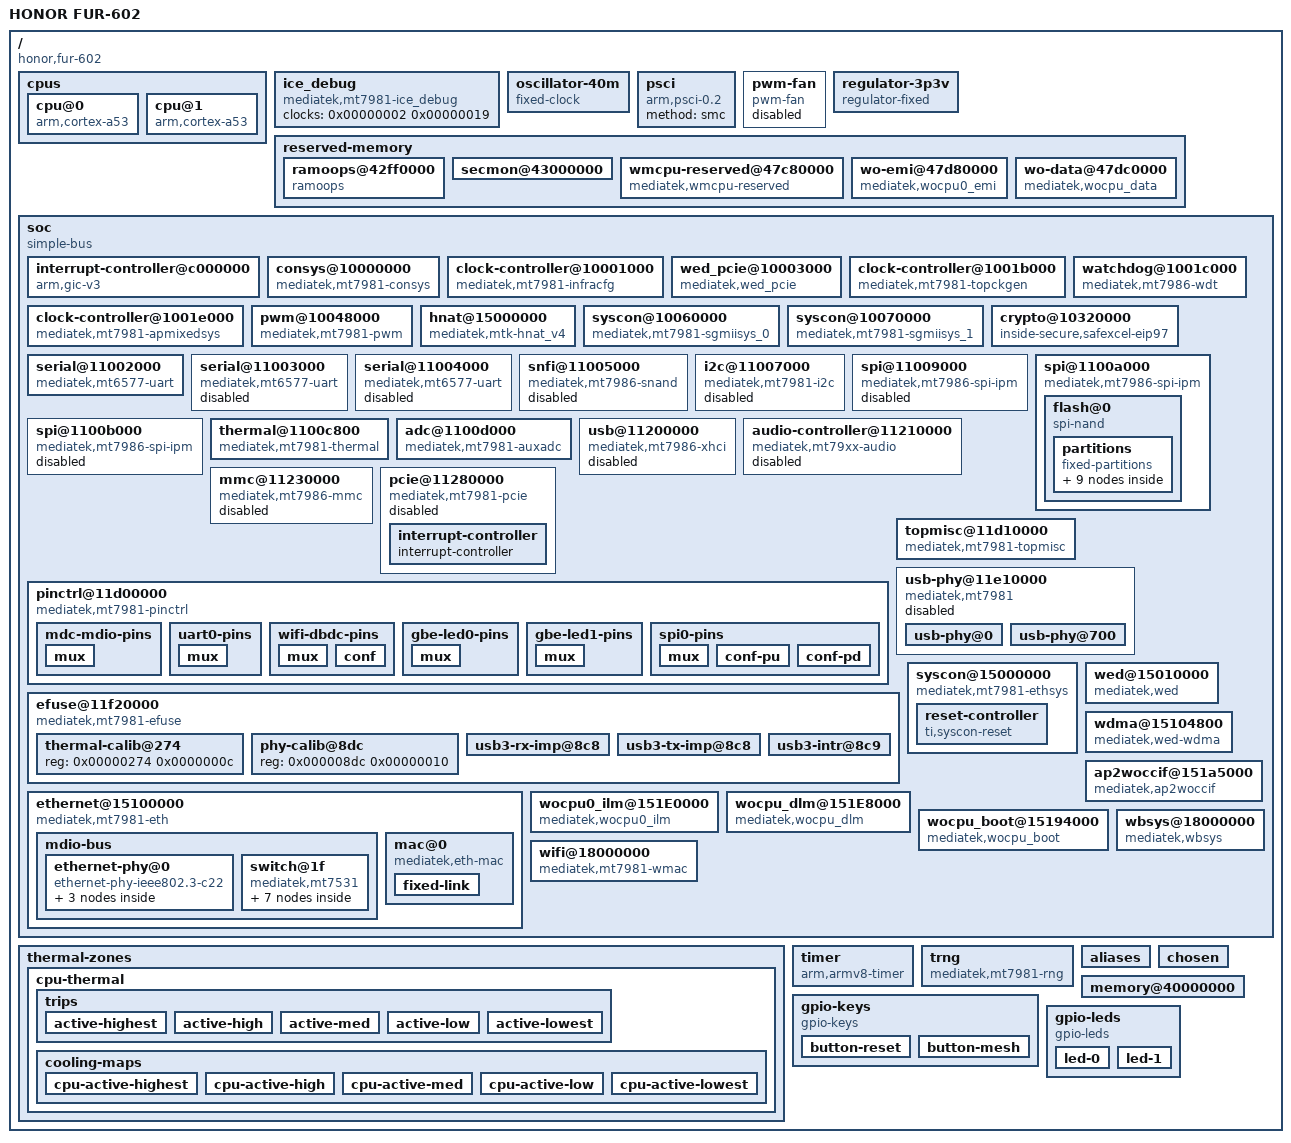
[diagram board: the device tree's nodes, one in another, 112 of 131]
/dts-v1/;
// version:		17
// last_comp_version:	16
// boot_cpuid_phys:	0x0

/ {
    mediatek,env-size = "0x20000";
    mediatek,env-offset = "0x0";
    mediatek,env-part = "u-boot-env";
    compatible = "honor,fur-602", "mediatek,mt7981";
    interrupt-parent = <0x00000001>;
    #address-cells = <0x00000002>;
    #size-cells = <0x00000002>;
    model = "HONOR FUR-602";
    cpus {
        #address-cells = <0x00000001>;
        #size-cells = <0x00000000>;
        cpu@0 {
            compatible = "arm,cortex-a53";
            reg = <0x00000000>;
            device_type = "cpu";
            enable-method = "psci";
        };
        cpu@1 {
            compatible = "arm,cortex-a53";
            reg = <0x00000001>;
            device_type = "cpu";
            enable-method = "psci";
        };
    };
    ice_debug {
        compatible = "mediatek,mt7981-ice_debug", "mediatek,mt2701-ice_debug";
        clocks = <0x00000002 0x00000019>;
        clock-names = "ice_dbg";
        phandle = <0x00000020>;
    };
    oscillator-40m {
        compatible = "fixed-clock";
        clock-frequency = <0x02625a00>;
        clock-output-names = "clkxtal";
        #clock-cells = <0x00000000>;
        phandle = <0x00000021>;
    };
    psci {
        compatible = "arm,psci-0.2";
        method = "smc";
    };
    pwm-fan {
        compatible = "pwm-fan";
        cooling-levels = <0x00000000 0x0000003f 0x0000005f 0x0000007f 0x0000009f 0x000000bf 0x000000df 0x000000ff>;
        #cooling-cells = <0x00000002>;
        status = "disabled";
        phandle = <0x0000001a>;
    };
    regulator-3p3v {
        compatible = "regulator-fixed";
        regulator-name = "fixed-3.3V";
        regulator-min-microvolt = <0x00325aa0>;
        regulator-max-microvolt = <0x00325aa0>;
        regulator-boot-on;
        regulator-always-on;
        phandle = <0x0000000d>;
    };
    reserved-memory {
        ranges;
        #address-cells = <0x00000002>;
        #size-cells = <0x00000002>;
        ramoops@42ff0000 {
            compatible = "ramoops";
            reg = <0x00000000 0x42ff0000 0x00000000 0x00010000>;
            record-size = <0x00001000>;
        };
        secmon@43000000 {
            reg = <0x00000000 0x43000000 0x00000000 0x00030000>;
            no-map;
            phandle = <0x00000022>;
        };
        wmcpu-reserved@47c80000 {
            compatible = "mediatek,wmcpu-reserved";
            reg = <0x00000000 0x47c80000 0x00000000 0x00100000>;
            no-map;
            phandle = <0x00000004>;
        };
        wo-emi@47d80000 {
            compatible = "mediatek,wocpu0_emi";
            reg = <0x00000000 0x47d80000 0x00000000 0x00040000>;
            no-map;
            shared = <0x00000000>;
            phandle = <0x00000023>;
        };
        wo-data@47dc0000 {
            compatible = "mediatek,wocpu_data";
            reg = <0x00000000 0x47dc0000 0x00000000 0x00240000>;
            no-map;
            shared = <0x00000001>;
            phandle = <0x00000024>;
        };
    };
    soc {
        compatible = "simple-bus";
        ranges;
        #address-cells = <0x00000002>;
        #size-cells = <0x00000002>;
        interrupt-controller@c000000 {
            compatible = "arm,gic-v3";
            reg = <0x00000000 0x0c000000 0x00000000 0x00040000 0x00000000 0x0c080000 0x00000000 0x00200000>;
            interrupt-parent = <0x00000001>;
            interrupts = <0x00000001 0x00000009 0x00000004>;
            interrupt-controller;
            #interrupt-cells = <0x00000003>;
            phandle = <0x00000001>;
        };
        consys@10000000 {
            compatible = "mediatek,mt7981-consys";
            reg = <0x00000000 0x10000000 0x00000000 0x08600000>;
            clocks = <0x00000003 0x0000005f 0x00000003 0x0000005c>;
            clock-names = "mcu", "ap2conn";
            memory-region = <0x00000004>;
            phandle = <0x00000025>;
        };
        clock-controller@10001000 {
            compatible = "mediatek,mt7981-infracfg", "syscon";
            reg = <0x00000000 0x10001000 0x00000000 0x00001000>;
            #clock-cells = <0x00000001>;
            phandle = <0x00000002>;
        };
        wed_pcie@10003000 {
            compatible = "mediatek,wed_pcie";
            reg = <0x00000000 0x10003000 0x00000000 0x00000010>;
            phandle = <0x00000026>;
        };
        clock-controller@1001b000 {
            compatible = "mediatek,mt7981-topckgen", "syscon";
            reg = <0x00000000 0x1001b000 0x00000000 0x00001000>;
            #clock-cells = <0x00000001>;
            phandle = <0x00000003>;
        };
        watchdog@1001c000 {
            compatible = "mediatek,mt7986-wdt", "mediatek,mt6589-wdt";
            reg = <0x00000000 0x1001c000 0x00000000 0x00001000>;
            interrupts = <0x00000000 0x0000006e 0x00000004>;
            #reset-cells = <0x00000001>;
            status = "okay";
            phandle = <0x00000027>;
        };
        clock-controller@1001e000 {
            compatible = "mediatek,mt7981-apmixedsys", "syscon";
            reg = <0x00000000 0x1001e000 0x00000000 0x00001000>;
            #clock-cells = <0x00000001>;
            phandle = <0x0000000a>;
        };
        pwm@10048000 {
            compatible = "mediatek,mt7981-pwm";
            reg = <0x00000000 0x10048000 0x00000000 0x00001000>;
            clocks = <0x00000002 0x0000000e 0x00000002 0x0000000d 0x00000002 0x0000000f 0x00000002 0x00000010 0x00000002 0x00000011>;
            clock-names = "top", "main", "pwm1", "pwm2", "pwm3";
            #pwm-cells = <0x00000002>;
            phandle = <0x00000028>;
        };
        hnat@15000000 {
            compatible = "mediatek,mtk-hnat_v4";
            reg = <0x00000000 0x15100000 0x00000000 0x00080000>;
            resets = <0x00000005 0x00000000>;
            reset-names = "mtketh";
            mtketh-wan = "eth1";
            mtketh-lan = "eth0";
            mtketh-max-gmac = <0x00000002>;
            mtketh-ppe-num = <0x00000002>;
            ext-devices-prefix = "usb", "wwan", "rmnet", "eth2", "eth3", "eth4";
            phandle = <0x00000029>;
        };
        syscon@10060000 {
            compatible = "mediatek,mt7981-sgmiisys_0", "syscon";
            reg = <0x00000000 0x10060000 0x00000000 0x00001000>;
            mediatek,pnswap;
            #clock-cells = <0x00000001>;
            phandle = <0x00000011>;
        };
        syscon@10070000 {
            compatible = "mediatek,mt7981-sgmiisys_1", "syscon";
            reg = <0x00000000 0x10070000 0x00000000 0x00001000>;
            #clock-cells = <0x00000001>;
            phandle = <0x00000012>;
        };
        crypto@10320000 {
            compatible = "inside-secure,safexcel-eip97";
            reg = <0x00000000 0x10320000 0x00000000 0x00040000>;
            interrupts = <0x00000000 0x00000074 0x00000004 0x00000000 0x00000075 0x00000004 0x00000000 0x00000076 0x00000004 0x00000000 0x00000077 0x00000004>;
            interrupt-names = "ring0", "ring1", "ring2", "ring3";
            clocks = <0x00000003 0x00000042>;
            clock-names = "top_eip97_ck";
            assigned-clocks = <0x00000003 0x00000063>;
            assigned-clock-parents = <0x00000003 0x00000015>;
            phandle = <0x0000002a>;
        };
        serial@11002000 {
            compatible = "mediatek,mt6577-uart";
            reg = <0x00000000 0x11002000 0x00000000 0x00000400>;
            interrupts = <0x00000000 0x0000007b 0x00000004>;
            clocks = <0x00000002 0x00000001 0x00000002 0x0000001f>;
            clock-names = "baud", "bus";
            assigned-clocks = <0x00000003 0x00000050 0x00000002 0x00000001>;
            assigned-clock-parents = <0x00000003 0x00000000 0x00000003 0x00000050>;
            pinctrl-0 = <0x00000006>;
            pinctrl-names = "default";
            status = "okay";
            phandle = <0x0000002b>;
        };
        serial@11003000 {
            compatible = "mediatek,mt6577-uart";
            reg = <0x00000000 0x11003000 0x00000000 0x00000400>;
            interrupts = <0x00000000 0x0000007c 0x00000004>;
            clocks = <0x00000002 0x00000002 0x00000002 0x00000020>;
            clock-names = "baud", "bus";
            assigned-clocks = <0x00000003 0x00000050 0x00000002 0x00000002>;
            assigned-clock-parents = <0x00000003 0x00000000 0x00000003 0x00000050>;
            status = "disabled";
            phandle = <0x0000002c>;
        };
        serial@11004000 {
            compatible = "mediatek,mt6577-uart";
            reg = <0x00000000 0x11004000 0x00000000 0x00000400>;
            interrupts = <0x00000000 0x0000007d 0x00000004>;
            clocks = <0x00000002 0x00000003 0x00000002 0x00000021>;
            clock-names = "baud", "bus";
            assigned-clocks = <0x00000003 0x00000050 0x00000002 0x00000003>;
            assigned-clock-parents = <0x00000003 0x00000000 0x00000003 0x00000050>;
            status = "disabled";
            phandle = <0x0000002d>;
        };
        snfi@11005000 {
            compatible = "mediatek,mt7986-snand";
            reg = <0x00000000 0x11005000 0x00000000 0x00001000 0x00000000 0x11006000 0x00000000 0x00001000>;
            reg-names = "nfi", "ecc";
            interrupts = <0x00000000 0x00000079 0x00000004>;
            clocks = <0x00000002 0x00000025 0x00000002 0x00000024 0x00000002 0x00000026>;
            clock-names = "pad_clk", "nfi_clk", "nfi_hclk";
            assigned-clocks = <0x00000003 0x0000004d 0x00000003 0x0000004c>;
            assigned-clock-parents = <0x00000003 0x00000006 0x00000003 0x00000006>;
            #address-cells = <0x00000001>;
            #size-cells = <0x00000000>;
            status = "disabled";
            phandle = <0x0000002e>;
        };
        i2c@11007000 {
            compatible = "mediatek,mt7981-i2c";
            reg = <0x00000000 0x11007000 0x00000000 0x00001000 0x00000000 0x10217080 0x00000000 0x00000080>;
            interrupts = <0x00000000 0x00000088 0x00000004>;
            clock-div = <0x00000001>;
            clocks = <0x00000002 0x0000001e 0x00000002 0x0000001a 0x00000002 0x00000033 0x00000002 0x00000034>;
            clock-names = "main", "dma", "arb", "pmic";
            #address-cells = <0x00000001>;
            #size-cells = <0x00000000>;
            status = "disabled";
            phandle = <0x0000002f>;
        };
        spi@11009000 {
            compatible = "mediatek,mt7986-spi-ipm", "mediatek,spi-ipm";
            reg = <0x00000000 0x11009000 0x00000000 0x00000100>;
            interrupts = <0x00000000 0x0000008e 0x00000004>;
            clocks = <0x00000003 0x00000002 0x00000003 0x0000004e 0x00000002 0x00000022 0x00000002 0x00000023>;
            clock-names = "parent-clk", "sel-clk", "spi-clk", "hclk";
            #address-cells = <0x00000001>;
            #size-cells = <0x00000000>;
            status = "disabled";
            phandle = <0x00000030>;
        };
        spi@1100a000 {
            compatible = "mediatek,mt7986-spi-ipm", "mediatek,spi-ipm";
            reg = <0x00000000 0x1100a000 0x00000000 0x00000100>;
            interrupts = <0x00000000 0x0000008c 0x00000004>;
            clocks = <0x00000003 0x00000002 0x00000003 0x0000004e 0x00000002 0x00000027 0x00000002 0x00000029>;
            clock-names = "parent-clk", "sel-clk", "spi-clk", "hclk";
            #address-cells = <0x00000001>;
            #size-cells = <0x00000000>;
            status = "okay";
            pinctrl-names = "default";
            pinctrl-0 = <0x00000007>;
            phandle = <0x00000031>;
            flash@0 {
                #address-cells = <0x00000001>;
                #size-cells = <0x00000001>;
                compatible = "spi-nand";
                reg = <0x00000000>;
                spi-max-frequency = <0x03197500>;
                spi-tx-bus-width = <0x00000004>;
                spi-rx-bus-width = <0x00000004>;
                spi-cal-enable;
                spi-cal-mode = "read-data";
                spi-cal-datalen = <0x00000007>;
                spi-cal-data = [53 50 49 4e 41 4e 44];
                spi-cal-addrlen = <0x00000005>;
                spi-cal-addr = <0x00000000 0x00000000 0x00000000 0x00000000 0x00000000>;
                mediatek,nmbm;
                mediatek,bmt-max-ratio = <0x00000001>;
                mediatek,bmt-max-reserved-blocks = <0x00000040>;
                phandle = <0x00000032>;
                partitions {
                    compatible = "fixed-partitions";
                    #address-cells = <0x00000001>;
                    #size-cells = <0x00000001>;
                    partition@0 {
                        label = "BL2";
                        reg = <0x00000000 0x00100000>;
                        read-only;
                    };
                    partition@100000 {
                        label = "u-boot-env";
                        reg = <0x00100000 0x00080000>;
                    };
                    partition@180000 {
                        label = "Factory";
                        reg = <0x00180000 0x001e0000>;
                        read-only;
                        nvmem-layout {
                            compatible = "fixed-layout";
                            #address-cells = <0x00000001>;
                            #size-cells = <0x00000001>;
                            eeprom@0 {
                                reg = <0x00000000 0x00001000>;
                                phandle = <0x00000018>;
                            };
                            macaddr@2a {
                                compatible = "mac-base";
                                reg = <0x0000002a 0x00000006>;
                                #nvmem-cell-cells = <0x00000001>;
                                phandle = <0x00000016>;
                            };
                        };
                    };
                    partition@360000 {
                        label = "Trace";
                        reg = <0x00360000 0x00020000>;
                        read-only;
                    };
                    partition@380000 {
                        label = "FIP";
                        reg = <0x00380000 0x00200000>;
                        read-only;
                    };
                    partition@580000 {
                        label = "ubi";
                        reg = <0x00580000 0x07200000>;
                    };
                };
            };
        };
        spi@1100b000 {
            compatible = "mediatek,mt7986-spi-ipm", "mediatek,spi-ipm";
            reg = <0x00000000 0x1100b000 0x00000000 0x00000100>;
            interrupts = <0x00000000 0x0000008d 0x00000004>;
            clocks = <0x00000003 0x00000002 0x00000003 0x0000004f 0x00000002 0x00000028 0x00000002 0x0000002a>;
            clock-names = "parent-clk", "sel-clk", "spi-clk", "hclk";
            #address-cells = <0x00000001>;
            #size-cells = <0x00000000>;
            status = "disabled";
            phandle = <0x00000033>;
        };
        thermal@1100c800 {
            compatible = "mediatek,mt7981-thermal", "mediatek,mt7986-thermal";
            reg = <0x00000000 0x1100c800 0x00000000 0x00000800>;
            interrupts = <0x00000000 0x0000008a 0x00000004>;
            clocks = <0x00000002 0x0000001d 0x00000002 0x00000030>;
            clock-names = "therm", "auxadc";
            nvmem-cells = <0x00000008>;
            nvmem-cell-names = "calibration-data";
            #thermal-sensor-cells = <0x00000001>;
            mediatek,auxadc = <0x00000009>;
            mediatek,apmixedsys = <0x0000000a>;
            phandle = <0x00000019>;
        };
        adc@1100d000 {
            compatible = "mediatek,mt7981-auxadc", "mediatek,mt7986-auxadc", "mediatek,mt7622-auxadc";
            reg = <0x00000000 0x1100d000 0x00000000 0x00001000>;
            clocks = <0x00000002 0x00000030 0x00000002 0x00000031>;
            clock-names = "main", "32k";
            #io-channel-cells = <0x00000001>;
            phandle = <0x00000009>;
        };
        usb@11200000 {
            compatible = "mediatek,mt7986-xhci", "mediatek,mtk-xhci";
            reg = <0x00000000 0x11200000 0x00000000 0x00002e00 0x00000000 0x11203e00 0x00000000 0x00000100>;
            reg-names = "mac", "ippc";
            interrupts = <0x00000000 0x000000ad 0x00000004>;
            clocks = <0x00000002 0x00000037 0x00000002 0x00000038 0x00000002 0x00000035 0x00000002 0x00000036 0x00000003 0x0000006b>;
            clock-names = "sys_ck", "ref_ck", "mcu_ck", "dma_ck", "xhci_ck";
            phys = <0x0000000b 0x00000003 0x0000000c 0x00000004>;
            vusb33-supply = <0x0000000d>;
            status = "disabled";
            phandle = <0x00000034>;
        };
        audio-controller@11210000 {
            compatible = "mediatek,mt79xx-audio";
            reg = <0x00000000 0x11210000 0x00000000 0x00009000>;
            interrupts = <0x00000000 0x0000006a 0x00000004>;
            clocks = <0x00000002 0x00000013 0x00000002 0x00000014 0x00000002 0x00000015 0x00000002 0x00000016 0x00000002 0x00000017 0x00000003 0x00000065>;
            clock-names = "aud_bus_ck", "aud_26m_ck", "aud_l_ck", "aud_aud_ck", "aud_eg2_ck", "aud_sel";
            assigned-clocks = <0x00000003 0x00000065 0x00000003 0x00000066 0x00000003 0x00000067 0x00000003 0x00000068>;
            assigned-clock-parents = <0x00000003 0x00000010 0x00000003 0x00000012 0x00000003 0x00000010 0x00000003 0x00000012>;
            status = "disabled";
            phandle = <0x00000035>;
        };
        mmc@11230000 {
            compatible = "mediatek,mt7986-mmc", "mediatek,mt7981-mmc";
            reg = <0x00000000 0x11230000 0x00000000 0x00001000 0x00000000 0x11c20000 0x00000000 0x00001000>;
            interrupts = <0x00000000 0x0000008f 0x00000004>;
            clocks = <0x00000002 0x0000002c 0x00000002 0x0000002d 0x00000002 0x0000002f 0x00000002 0x0000002e>;
            assigned-clocks = <0x00000003 0x00000054 0x00000003 0x00000055>;
            assigned-clock-parents = <0x00000003 0x00000002 0x00000003 0x0000001c>;
            clock-names = "source", "hclk", "axi_cg", "ahb_cg";
            status = "disabled";
            phandle = <0x00000036>;
        };
        pcie@11280000 {
            compatible = "mediatek,mt7981-pcie", "mediatek,mt8192-pcie";
            reg = <0x00000000 0x11280000 0x00000000 0x00004000>;
            reg-names = "pcie-mac";
            ranges = <0x82000000 0x00000000 0x20000000 0x00000000 0x20000000 0x00000000 0x10000000>;
            device_type = "pci";
            interrupts = <0x00000000 0x000000a8 0x00000004>;
            bus-range = <0x00000000 0x000000ff>;
            clocks = <0x00000002 0x00000039 0x00000002 0x0000003a 0x00000002 0x0000003b 0x00000002 0x0000003c>;
            phys = <0x0000000c 0x00000002>;
            phy-names = "pcie-phy";
            interrupt-map-mask = <0x00000000 0x00000000 0x00000000 0x00000007>;
            interrupt-map = <0x00000000 0x00000000 0x00000000 0x00000001 0x0000000e 0x00000000 0x00000000 0x00000000 0x00000000 0x00000002 0x0000000e 0x00000001 0x00000000 0x00000000 0x00000000 0x00000003 0x0000000e 0x00000002 0x00000000 0x00000000 0x00000000 0x00000004 0x0000000e 0x00000003>;
            #interrupt-cells = <0x00000001>;
            #address-cells = <0x00000003>;
            #size-cells = <0x00000002>;
            status = "disabled";
            phandle = <0x00000037>;
            interrupt-controller {
                interrupt-controller;
                #interrupt-cells = <0x00000001>;
                #address-cells = <0x00000000>;
                phandle = <0x0000000e>;
            };
        };
        pinctrl@11d00000 {
            compatible = "mediatek,mt7981-pinctrl";
            reg = <0x00000000 0x11d00000 0x00000000 0x00001000 0x00000000 0x11c00000 0x00000000 0x00001000 0x00000000 0x11c10000 0x00000000 0x00001000 0x00000000 0x11d20000 0x00000000 0x00001000 0x00000000 0x11e00000 0x00000000 0x00001000 0x00000000 0x11e20000 0x00000000 0x00001000 0x00000000 0x11f00000 0x00000000 0x00001000 0x00000000 0x11f10000 0x00000000 0x00001000 0x00000000 0x1000b000 0x00000000 0x00001000>;
            reg-names = "gpio", "iocfg_rt", "iocfg_rm", "iocfg_rb", "iocfg_lb", "iocfg_bl", "iocfg_tm", "iocfg_tl", "eint";
            gpio-controller;
            #gpio-cells = <0x00000002>;
            gpio-ranges = <0x0000000f 0x00000000 0x00000000 0x00000038>;
            interrupt-controller;
            interrupts = <0x00000000 0x000000e1 0x00000004>;
            interrupt-parent = <0x00000001>;
            #interrupt-cells = <0x00000002>;
            phandle = <0x0000000f>;
            mdc-mdio-pins {
                phandle = <0x00000038>;
                mux {
                    function = "eth";
                    groups = "smi_mdc_mdio";
                };
            };
            uart0-pins {
                phandle = <0x00000006>;
                mux {
                    function = "uart";
                    groups = "uart0";
                };
            };
            wifi-dbdc-pins {
                phandle = <0x00000039>;
                mux {
                    function = "eth";
                    groups = "wf0_mode1";
                };
                conf {
                    pins = "WF_HB1", "WF_HB2", "WF_HB3", "WF_HB4", "WF_HB0", "WF_HB0_B", "WF_HB5", "WF_HB6", "WF_HB7", "WF_HB8", "WF_HB9", "WF_HB10", "WF_TOP_CLK", "WF_TOP_DATA", "WF_XO_REQ", "WF_CBA_RESETB", "WF_DIG_RESETB";
                    drive-strength = <0x00000004>;
                };
            };
            gbe-led0-pins {
                phandle = <0x0000003a>;
                mux {
                    function = "led";
                    groups = "gbe_led0";
                };
            };
            gbe-led1-pins {
                phandle = <0x0000003b>;
                mux {
                    function = "led";
                    groups = "gbe_led1";
                };
            };
            spi0-pins {
                phandle = <0x00000007>;
                mux {
                    function = "spi";
                    groups = "spi0", "spi0_wp_hold";
                };
                conf-pu {
                    pins = "SPI0_CS", "SPI0_HOLD", "SPI0_WP";
                    drive-strength = <0x00000008>;
                    bias-pull-up = <0x00000067>;
                };
                conf-pd {
                    pins = "SPI0_CLK", "SPI0_MOSI", "SPI0_MISO";
                    drive-strength = <0x00000008>;
                    bias-pull-down = <0x00000067>;
                };
            };
        };
        topmisc@11d10000 {
            compatible = "mediatek,mt7981-topmisc", "syscon";
            reg = <0x00000000 0x11d10000 0x00000000 0x00010000>;
            #clock-cells = <0x00000001>;
            phandle = <0x00000010>;
        };
        usb-phy@11e10000 {
            compatible = "mediatek,mt7981", "mediatek,generic-tphy-v2";
            ranges = <0x00000000 0x00000000 0x11e10000 0x00001700>;
            #address-cells = <0x00000001>;
            #size-cells = <0x00000001>;
            status = "disabled";
            phandle = <0x0000003c>;
            usb-phy@0 {
                reg = <0x00000000 0x00000700>;
                clocks = <0x00000003 0x0000006c>;
                clock-names = "ref";
                #phy-cells = <0x00000001>;
                phandle = <0x0000000b>;
            };
            usb-phy@700 {
                reg = <0x00000700 0x00000900>;
                clocks = <0x00000003 0x00000064>;
                clock-names = "ref";
                #phy-cells = <0x00000001>;
                mediatek,syscon-type = <0x00000010 0x00000218 0x00000000>;
                status = "okay";
                phandle = <0x0000000c>;
            };
        };
        efuse@11f20000 {
            compatible = "mediatek,mt7981-efuse", "mediatek,efuse";
            reg = <0x00000000 0x11f20000 0x00000000 0x00001000>;
            #address-cells = <0x00000001>;
            #size-cells = <0x00000001>;
            status = "okay";
            phandle = <0x0000003d>;
            thermal-calib@274 {
                reg = <0x00000274 0x0000000c>;
                phandle = <0x00000008>;
            };
            phy-calib@8dc {
                reg = <0x000008dc 0x00000010>;
                phandle = <0x00000014>;
            };
            usb3-rx-imp@8c8 {
                reg = <0x000008c8 0x00000001>;
                bits = <0x00000000 0x00000005>;
                phandle = <0x0000003e>;
            };
            usb3-tx-imp@8c8 {
                reg = <0x000008c8 0x00000002>;
                bits = <0x00000005 0x00000005>;
                phandle = <0x0000003f>;
            };
            usb3-intr@8c9 {
                reg = <0x000008c9 0x00000001>;
                bits = <0x00000002 0x00000006>;
                phandle = <0x00000040>;
            };
        };
        syscon@15000000 {
            #address-cells = <0x00000001>;
            #size-cells = <0x00000001>;
            compatible = "mediatek,mt7981-ethsys", "syscon";
            reg = <0x00000000 0x15000000 0x00000000 0x00001000>;
            #clock-cells = <0x00000001>;
            #reset-cells = <0x00000001>;
            phandle = <0x00000005>;
            reset-controller {
                compatible = "ti,syscon-reset";
                #reset-cells = <0x00000001>;
                ti,reset-bits = <0x00000034 0x00000004 0x00000034 0x00000004 0x00000034 0x00000004 0x00000028>;
                phandle = <0x00000017>;
            };
        };
        wed@15010000 {
            compatible = "mediatek,wed";
            wed_num = <0x00000002>;
            pci_slot_map = <0x00000000 0x00000001>;
            reg = <0x00000000 0x15010000 0x00000000 0x00001000 0x00000000 0x15011000 0x00000000 0x00001000>;
            interrupt-parent = <0x00000001>;
            interrupts = <0x00000000 0x000000cd 0x00000004 0x00000000 0x000000ce 0x00000004>;
            phandle = <0x00000013>;
        };
        wdma@15104800 {
            compatible = "mediatek,wed-wdma";
            reg = <0x00000000 0x15104800 0x00000000 0x00000400 0x00000000 0x15104c00 0x00000000 0x00000400>;
            phandle = <0x00000041>;
        };
        ethernet@15100000 {
            compatible = "mediatek,mt7981-eth";
            reg = <0x00000000 0x15100000 0x00000000 0x00080000>;
            interrupts = <0x00000000 0x000000bd 0x00000004 0x00000000 0x000000be 0x00000004 0x00000000 0x000000bf 0x00000004 0x00000000 0x000000c0 0x00000004 0x00000000 0x000000c4 0x00000004 0x00000000 0x000000c5 0x00000004 0x00000000 0x000000c6 0x00000004 0x00000000 0x000000c7 0x00000004>;
            clocks = <0x00000005 0x00000000 0x00000005 0x00000001 0x00000005 0x00000002 0x00000005 0x00000003 0x00000011 0x00000000 0x00000011 0x00000001 0x00000011 0x00000002 0x00000011 0x00000003 0x00000012 0x00000000 0x00000012 0x00000001 0x00000012 0x00000002 0x00000012 0x00000003 0x00000003 0x00000040 0x00000003 0x0000005d 0x00000003 0x0000005e>;
            clock-names = "fe", "gp2", "gp1", "wocpu0", "sgmii_tx250m", "sgmii_rx250m", "sgmii_cdr_ref", "sgmii_cdr_fb", "sgmii2_tx250m", "sgmii2_rx250m", "sgmii2_cdr_ref", "sgmii2_cdr_fb", "sgmii_ck", "netsys0", "netsys1";
            assigned-clocks = <0x00000003 0x00000060 0x00000003 0x00000061>;
            assigned-clock-parents = <0x00000003 0x0000001b 0x00000003 0x00000022>;
            mediatek,ethsys = <0x00000005>;
            mediatek,sgmiisys = <0x00000011 0x00000012>;
            mediatek,infracfg = <0x00000010>;
            mediatek,wed = <0x00000013>;
            #reset-cells = <0x00000001>;
            #address-cells = <0x00000001>;
            #size-cells = <0x00000000>;
            status = "okay";
            phandle = <0x00000042>;
            mdio-bus {
                #address-cells = <0x00000001>;
                #size-cells = <0x00000000>;
                phandle = <0x00000043>;
                ethernet-phy@0 {
                    compatible = "ethernet-phy-ieee802.3-c22";
                    reg = <0x00000000>;
                    phy-mode = "gmii";
                    phy-is-integrated;
                    nvmem-cells = <0x00000014>;
                    nvmem-cell-names = "phy-cal-data";
                    phandle = <0x00000044>;
                    leds {
                        #address-cells = <0x00000001>;
                        #size-cells = <0x00000000>;
                        int-gbe-phy-led0@0 {
                            reg = <0x00000000>;
                            function = "lan";
                            status = "disabled";
                            phandle = <0x00000045>;
                        };
                        int-gbe-phy-led1@1 {
                            reg = <0x00000001>;
                            function = "lan";
                            status = "disabled";
                            phandle = <0x00000046>;
                        };
                    };
                };
                switch@1f {
                    compatible = "mediatek,mt7531";
                    reg = <0x0000001f>;
                    reset-gpios = <0x0000000f 0x00000027 0x00000000>;
                    interrupt-controller;
                    #interrupt-cells = <0x00000001>;
                    interrupt-parent = <0x0000000f>;
                    interrupts = <0x00000026 0x00000004>;
                    phandle = <0x00000047>;
                    ports {
                        #address-cells = <0x00000001>;
                        #size-cells = <0x00000000>;
                        port@0 {
                            reg = <0x00000000>;
                            label = "wan";
                        };
                        port@1 {
                            reg = <0x00000001>;
                            label = "lan3";
                        };
                        port@2 {
                            reg = <0x00000002>;
                            label = "lan2";
                        };
                        port@3 {
                            reg = <0x00000003>;
                            label = "lan1";
                        };
                        port@6 {
                            reg = <0x00000006>;
                            ethernet = <0x00000015>;
                            phy-mode = "2500base-x";
                            fixed-link {
                                speed = <0x000009c4>;
                                full-duplex;
                                pause;
                            };
                        };
                    };
                };
            };
            mac@0 {
                compatible = "mediatek,eth-mac";
                reg = <0x00000000>;
                phy-mode = "2500base-x";
                nvmem-cells = <0x00000016 0x00000000>;
                nvmem-cell-names = "mac-address";
                phandle = <0x00000015>;
                fixed-link {
                    speed = <0x000009c4>;
                    full-duplex;
                    pause;
                };
            };
        };
        ap2woccif@151a5000 {
            compatible = "mediatek,ap2woccif";
            reg = <0x00000000 0x151a5000 0x00000000 0x00001000 0x00000000 0x151ad000 0x00000000 0x00001000>;
            interrupt-parent = <0x00000001>;
            interrupts = <0x00000000 0x000000d3 0x00000004 0x00000000 0x000000d4 0x00000004>;
            phandle = <0x00000048>;
        };
        wocpu0_ilm@151E0000 {
            compatible = "mediatek,wocpu0_ilm";
            reg = <0x00000000 0x151e0000 0x00000000 0x00008000>;
            phandle = <0x00000049>;
        };
        wocpu_dlm@151E8000 {
            compatible = "mediatek,wocpu_dlm";
            reg = <0x00000000 0x151e8000 0x00000000 0x00002000 0x00000000 0x151f8000 0x00000000 0x00002000>;
            resets = <0x00000017 0x00000000>;
            reset-names = "wocpu_rst";
            phandle = <0x0000004a>;
        };
        wocpu_boot@15194000 {
            compatible = "mediatek,wocpu_boot";
            reg = <0x00000000 0x15194000 0x00000000 0x00001000>;
            phandle = <0x0000004b>;
        };
        wifi@18000000 {
            compatible = "mediatek,mt7981-wmac";
            nvmem-cells = <0x00000018>;
            nvmem-cell-names = "eeprom";
            status = "okay";
            phandle = <0x0000004c>;
        };
        wbsys@18000000 {
            compatible = "mediatek,wbsys";
            reg = <0x00000000 0x18000000 0x00000000 0x01000000>;
            interrupts = <0x00000000 0x000000d5 0x00000004 0x00000000 0x000000d6 0x00000004 0x00000000 0x000000d7 0x00000004 0x00000000 0x000000d8 0x00000004>;
            chip_id = <0x00007981>;
            phandle = <0x0000004d>;
        };
    };
    thermal-zones {
        cpu-thermal {
            polling-delay-passive = <0x000003e8>;
            polling-delay = <0x000003e8>;
            thermal-sensors = <0x00000019 0x00000000>;
            phandle = <0x0000004e>;
            trips {
                active-highest {
                    temperature = <0x00011170>;
                    hysteresis = <0x000007d0>;
                    type = "active";
                    phandle = <0x0000001b>;
                };
                active-high {
                    temperature = <0x0000ea60>;
                    hysteresis = <0x000007d0>;
                    type = "active";
                    phandle = <0x0000001c>;
                };
                active-med {
                    temperature = <0x0000c350>;
                    hysteresis = <0x000007d0>;
                    type = "active";
                    phandle = <0x0000001d>;
                };
                active-low {
                    temperature = <0x0000afc8>;
                    hysteresis = <0x000007d0>;
                    type = "active";
                    phandle = <0x0000001e>;
                };
                active-lowest {
                    temperature = <0x00009c40>;
                    hysteresis = <0x000007d0>;
                    type = "active";
                    phandle = <0x0000001f>;
                };
            };
            cooling-maps {
                cpu-active-highest {
                    cooling-device = <0x0000001a 0x00000007 0x00000007>;
                    trip = <0x0000001b>;
                };
                cpu-active-high {
                    cooling-device = <0x0000001a 0x00000005 0x00000005>;
                    trip = <0x0000001c>;
                };
                cpu-active-med {
                    cooling-device = <0x0000001a 0x00000003 0x00000003>;
                    trip = <0x0000001d>;
                };
                cpu-active-low {
                    cooling-device = <0x0000001a 0x00000002 0x00000002>;
                    trip = <0x0000001e>;
                };
                cpu-active-lowest {
                    cooling-device = <0x0000001a 0x00000001 0x00000001>;
                    trip = <0x0000001f>;
                };
            };
        };
    };
    timer {
        compatible = "arm,armv8-timer";
        interrupt-parent = <0x00000001>;
        clock-frequency = <0x00c65d40>;
        interrupts = <0x00000001 0x0000000d 0x00000008 0x00000001 0x0000000e 0x00000008 0x00000001 0x0000000b 0x00000008 0x00000001 0x0000000a 0x00000008>;
    };
    trng {
        compatible = "mediatek,mt7981-rng";
    };
    aliases {
        led-boot = "/gpio-leds/led-1";
        led-failsafe = "/gpio-leds/led-1";
        led-running = "/gpio-leds/led-0";
        led-upgrade = "/gpio-leds/led-0";
        serial0 = "/soc/serial@11002000";
    };
    chosen {
        u-boot,bootconf = "config-1";
        u-boot,version = "2025.07.1-Mediatek";
        stdout-path = "serial0:115200n8";
    };
    memory@40000000 {
        device_type = "memory";
        reg = <0x00000000 0x40000000 0x00000000 0x10000000>;
    };
    gpio-keys {
        compatible = "gpio-keys";
        button-reset {
            label = "reset";
            linux,code = <0x00000198>;
            gpios = <0x0000000f 0x00000001 0x00000001>;
        };
        button-mesh {
            label = "mesh";
            linux,code = <0x00000109>;
            linux,input-type = <0x00000005>;
            gpios = <0x0000000f 0x00000000 0x00000001>;
        };
    };
    gpio-leds {
        compatible = "gpio-leds";
        led-0 {
            label = "green:status";
            gpios = <0x0000000f 0x00000008 0x00000001>;
            default-state = "off";
            phandle = <0x0000004f>;
        };
        led-1 {
            label = "red:status";
            gpios = <0x0000000f 0x0000000d 0x00000001>;
            default-state = "off";
            phandle = <0x00000050>;
        };
    };
    __symbols__ {
        ice = "/ice_debug";
        clk40m = "/oscillator-40m";
        fan = "/pwm-fan";
        reg_3p3v = "/regulator-3p3v";
        secmon_reserved = "/reserved-memory/secmon@43000000";
        wmcpu_emi = "/reserved-memory/wmcpu-reserved@47c80000";
        wo_emi0 = "/reserved-memory/wo-emi@47d80000";
        wo_data = "/reserved-memory/wo-data@47dc0000";
        gic = "/soc/interrupt-controller@c000000";
        consys = "/soc/consys@10000000";
        infracfg = "/soc/clock-controller@10001000";
        wed_pcie = "/soc/wed_pcie@10003000";
        topckgen = "/soc/clock-controller@1001b000";
        watchdog = "/soc/watchdog@1001c000";
        apmixedsys = "/soc/clock-controller@1001e000";
        pwm = "/soc/pwm@10048000";
        hnat = "/soc/hnat@15000000";
        sgmiisys0 = "/soc/syscon@10060000";
        sgmiisys1 = "/soc/syscon@10070000";
        crypto = "/soc/crypto@10320000";
        uart0 = "/soc/serial@11002000";
        uart1 = "/soc/serial@11003000";
        uart2 = "/soc/serial@11004000";
        snand = "/soc/snfi@11005000";
        i2c0 = "/soc/i2c@11007000";
        spi2 = "/soc/spi@11009000";
        spi0 = "/soc/spi@1100a000";
        spi_nand = "/soc/spi@1100a000/flash@0";
        eeprom_factory_0 = "/soc/spi@1100a000/flash@0/partitions/partition@180000/nvmem-layout/eeprom@0";
        macaddr_factory_2a = "/soc/spi@1100a000/flash@0/partitions/partition@180000/nvmem-layout/macaddr@2a";
        spi1 = "/soc/spi@1100b000";
        thermal = "/soc/thermal@1100c800";
        auxadc = "/soc/adc@1100d000";
        xhci = "/soc/usb@11200000";
        afe = "/soc/audio-controller@11210000";
        mmc0 = "/soc/mmc@11230000";
        pcie = "/soc/pcie@11280000";
        pcie_intc = "/soc/pcie@11280000/interrupt-controller";
        pio = "/soc/pinctrl@11d00000";
        mdio_pins = "/soc/pinctrl@11d00000/mdc-mdio-pins";
        uart0_pins = "/soc/pinctrl@11d00000/uart0-pins";
        wifi_dbdc_pins = "/soc/pinctrl@11d00000/wifi-dbdc-pins";
        gbe_led0_pins = "/soc/pinctrl@11d00000/gbe-led0-pins";
        gbe_led1_pins = "/soc/pinctrl@11d00000/gbe-led1-pins";
        spi0_flash_pins = "/soc/pinctrl@11d00000/spi0-pins";
        topmisc = "/soc/topmisc@11d10000";
        usb_phy = "/soc/usb-phy@11e10000";
        u2port0 = "/soc/usb-phy@11e10000/usb-phy@0";
        u3port0 = "/soc/usb-phy@11e10000/usb-phy@700";
        efuse = "/soc/efuse@11f20000";
        thermal_calibration = "/soc/efuse@11f20000/thermal-calib@274";
        phy_calibration = "/soc/efuse@11f20000/phy-calib@8dc";
        comb_rx_imp_p0 = "/soc/efuse@11f20000/usb3-rx-imp@8c8";
        comb_tx_imp_p0 = "/soc/efuse@11f20000/usb3-tx-imp@8c8";
        comb_intr_p0 = "/soc/efuse@11f20000/usb3-intr@8c9";
        ethsys = "/soc/syscon@15000000";
        ethsysrst = "/soc/syscon@15000000/reset-controller";
        wed = "/soc/wed@15010000";
        wdma = "/soc/wdma@15104800";
        eth = "/soc/ethernet@15100000";
        mdio_bus = "/soc/ethernet@15100000/mdio-bus";
        int_gbe_phy = "/soc/ethernet@15100000/mdio-bus/ethernet-phy@0";
        int_gbe_phy_led0 = "/soc/ethernet@15100000/mdio-bus/ethernet-phy@0/leds/int-gbe-phy-led0@0";
        int_gbe_phy_led1 = "/soc/ethernet@15100000/mdio-bus/ethernet-phy@0/leds/int-gbe-phy-led1@1";
        switch = "/soc/ethernet@15100000/mdio-bus/switch@1f";
        gmac0 = "/soc/ethernet@15100000/mac@0";
        ap2woccif = "/soc/ap2woccif@151a5000";
        wocpu0_ilm = "/soc/wocpu0_ilm@151E0000";
        wocpu_dlm = "/soc/wocpu_dlm@151E8000";
        cpu_boot = "/soc/wocpu_boot@15194000";
        wifi = "/soc/wifi@18000000";
        wbsys = "/soc/wbsys@18000000";
        cpu_thermal = "/thermal-zones/cpu-thermal";
        cpu_trip_active_highest = "/thermal-zones/cpu-thermal/trips/active-highest";
        cpu_trip_active_high = "/thermal-zones/cpu-thermal/trips/active-high";
        cpu_trip_active_med = "/thermal-zones/cpu-thermal/trips/active-med";
        cpu_trip_active_low = "/thermal-zones/cpu-thermal/trips/active-low";
        cpu_trip_active_lowest = "/thermal-zones/cpu-thermal/trips/active-lowest";
        status_green_led = "/gpio-leds/led-0";
        status_red_led = "/gpio-leds/led-1";
    };
};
